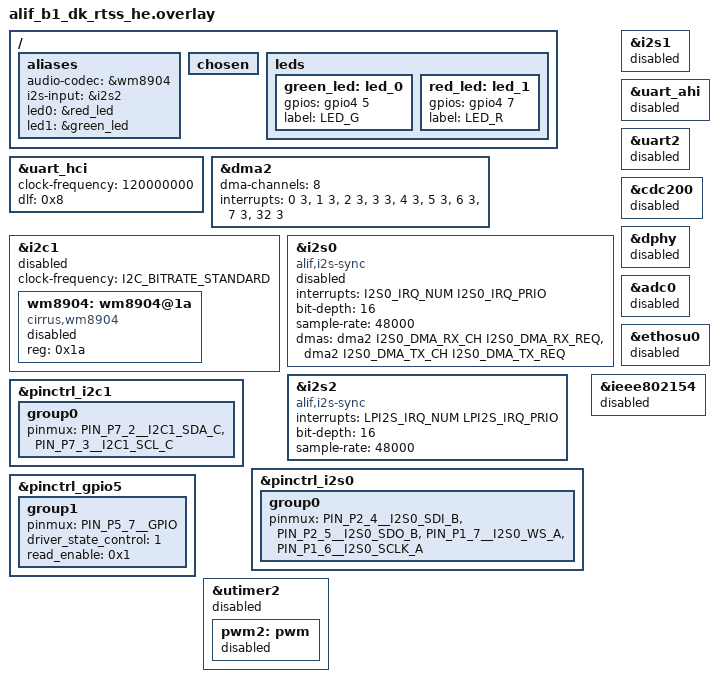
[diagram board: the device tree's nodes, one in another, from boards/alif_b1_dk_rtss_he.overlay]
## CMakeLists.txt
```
# Copyright (C) 2023 Alif Semiconductor - All Rights Reserved.
# Use, distribution and modification of this code is permitted under the
# terms stated in the Alif Semiconductor Software License Agreement
#
# You should have received a copy of the Alif Semiconductor Software
# License Agreement with this file. If not, please write to:
# contact@alifsemi.com, or visit: https://alifsemi.com/license

cmake_minimum_required(VERSION 3.20.0)
find_package(Zephyr REQUIRED HINTS $ENV{ZEPHYR_BASE})
project(le_audio_broadcast_source)

target_sources(app PRIVATE
    src/main.c
    src/broadcast_source.c
    src/audio_datapath.c
    src/mic_source.c
    src/power_config.c
)
```

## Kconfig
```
#Copyright(C) 2023 Alif Semiconductor - All Rights Reserved.
#Use, distribution and modification of this code is permitted under the
#terms stated in the Alif Semiconductor Software License Agreement
#
#You should have received a copy of the Alif Semiconductor Software
#License Agreement with this file.If not, please write to:
#contact @alifsemi.com, or visit : https: // alifsemi.com/license

menu "Alif Bluetooth LE Audio Broadcast Source"

config BLE_DEVICE_NAME
	string "BLE device name"
	default "ALIF_ZEPHYR"
	help
	  Device name to be included in advertising packets

config BROADCAST_NAME
	string "LE audio broadcast name"
	default "ALIF_LE_AUDIO"

config LE_AUDIO_PRESENTATION_DELAY_MS
	int "Presentation delay in ms"
	default 40
	help
	  LE audio presentation delay in ms. For the audio source use-case, this is defined as the
	  time in ms from the start of recording an audio frame, to the SDU reference anchor point
	  at which the SDU containing the same audio frame is sent over BLE. The absolute minimum
	  possible presentation delay would be the frame length (10 ms) plus the encoding time of
	  the frame, since it is impossible to send the frame before it has been fully recorded and
	  encoded. But some margin should be added on top of this to account for any overhead and
	  timing variations due to other activities of the software occurring while recording and
	  encoding the audio.

config APP_PRINT_STATS
	bool "Print info about send SDUs"
	depends on LOG

config APP_PRINT_STATS_INTERVAL
	int "Interval for printing info about send frames, in SDU count"
	default 1024
	depends on APP_PRINT_STATS
	help
	  Interval at which to print presentation delay statistics. The interval is measured in SDU
	  count, e.g. 1024 means to print the statistics every 512 SDUs (per channel). With a 10 ms
	  SDU interval this is around 10 seconds.

config MICROPHONE_GAIN
	int "Microphone gain in percentage"
	default 800
	range 100 1000

config INPUT_VOLUME_LEVEL
	int "Input volume level in percentage when MIC input is active"
	default 33
	range 10 100

config POWER_CONFIGURATION
	bool "Power configuration"
	default n

menu "Logging"

module = MAIN
module-str = main
source "subsys/logging/Kconfig.template.log_config"

module = BROADCAST_SOURCE
module-str = broadcast_source
source "subsys/logging/Kconfig.template.log_config"

module = AUDIO_DATAPATH
module-str = audio_datapath
source "subsys/logging/Kconfig.template.log_config"

endmenu # "Logging"

endmenu # "Alif Bluetooth LE Audio Broadcast Source"

source "Kconfig.zephyr"
```

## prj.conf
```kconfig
# Copyright (C) 2023 Alif Semiconductor - All Rights Reserved.
# Use, distribution and modification of this code is permitted under the
# terms stated in the Alif Semiconductor Software License Agreement
#
# You should have received a copy of the Alif Semiconductor Software
# License Agreement with this file. If not, please write to:
# contact@alifsemi.com, or visit: https://alifsemi.com/license
CONFIG_BT=y
CONFIG_BT_CUSTOM=y
CONFIG_ALIF_ROM_LC3_CODEC=y
CONFIG_ALIF_BLE_AUDIO=y

# CONFIG_TIMER_READS_ITS_FREQUENCY_AT_RUNTIME=y
#CONFIG_SYS_CLOCK_HW_CYCLES_PER_SEC=160000000
CONFIG_SYS_CLOCK_HW_CYCLES_PER_SEC=120000000
# not sure whether these are working or not...
#CONFIG_SYS_CLOCK_HW_CYCLES_PER_SEC=80000000
#CONFIG_SYS_CLOCK_HW_CYCLES_PER_SEC=60000000

CONFIG_USE_DYNAMIC_CLOCK_ADJUSTMENT=n
CONFIG_ALIF_BLE_SYNC_TIMER_UTIMER_ENABLED=n
CONFIG_POWER_CONFIGURATION=n

#CONFIG_LOG=y
#CONFIG_LOG_MODE_IMMEDIATE=y
#CONFIG_LOG_MODE_MINIMAL=y
CONFIG_CONSOLE=n
CONFIG_UART_CONSOLE=n
CONFIG_PRINTK=n

CONFIG_PRESENTATION_COMPENSATION_DIRECTION_SOURCE=y

CONFIG_AUDIO=y
CONFIG_AUDIO_CODEC=y
# CONFIG_AUDIO_CODEC_SHELL=y
# CONFIG_SHELL=y

# This is specific to whichever clock you use. Currently presentation layer is
# commented out so this does nothing
CONFIG_AUDIO_CLOCK_DIVIDER=1

# Should be replaced by TRNG when support is available
CONFIG_TEST_RANDOM_GENERATOR=y

# malloc support is required, simplest way is using newlib although it would also be possible to
# configure heap for picolibc
CONFIG_NEWLIB_LIBC=y

# Driver support for audio
CONFIG_I2S=y
CONFIG_I2S_SYNC_BUFFER_FORMAT_SEQUENTIAL=n
CONFIG_DMA=y

CONFIG_BROADCAST_NAME="ALIF_LE_AUDIO"

# Audio driver support specific to B1 DK board.
# Audio codec is WM8904, connected via I2C.
CONFIG_I2C=y
CONFIG_WM8904=y

CONFIG_I2C_INIT_PRIORITY=50
CONFIG_WM8904_INIT_PRIORITY=99

# For MRAM(XIP) builds with LLVM exception tables cause linker errors as part of the code is placed to TCM
CONFIG_EXCEPTIONS=n
```

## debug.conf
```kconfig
CONFIG_LOG=y
CONFIG_LOG_MODE_IMMEDIATE=y
CONFIG_LOG_MODE_MINIMAL=y
CONFIG_CONSOLE=y
CONFIG_UART_CONSOLE=y
```

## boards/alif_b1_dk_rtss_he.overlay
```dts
/* Copyright (C) 2023 Alif Semiconductor - All Rights Reserved.
 * Use, distribution and modification of this code is permitted under the
 * terms stated in the Alif Semiconductor Software License Agreement
 *
 * You should have received a copy of the Alif Semiconductor Software
 * License Agreement with this file. If not, please write to:
 * contact@alifsemi.com, or visit: https: //alifsemi.com/license
 *
 */

#include <dt-bindings/pinctrl/balletto-pinctrl.h>
#include <dt-bindings/i2c/i2c.h>
#include <dt-bindings/gpio/gpio.h>

#define I2S0_IRQ_NUM  141
#define I2S0_IRQ_PRIO 3

#define LPI2S_IRQ_NUM  48
#define LPI2S_IRQ_PRIO 3

#define I2S0_DMA_RX_CH  2
#define I2S0_DMA_RX_REQ 24
#define I2S0_DMA_TX_CH  3
#define I2S0_DMA_TX_REQ 28

#define LPI2S_DMA_RX_CH  4
#define LPI2S_DMA_RX_REQ 14
#define LPI2S_DMA_TX_CH  5
#define LPI2S_DMA_TX_REQ 15

#define AUDIO_DMA_ENABLED 1
/* TODO: check MIC DMA for some weird error when used multiple times */
#define MIC_DMA_ENABLED 0

#define HW_CORE_CLOCK 120

/ {
	aliases {
		audio-codec = &wm8904;
		i2s-input = &i2s2;
		/*i2s-mic = &i2s2;*/

		led0 = &red_led;
		led1 = &green_led;
	};

	chosen {
		/delete-property/ zephyr,console;
		/delete-property/ zephyr,shell-uart;
		/delete-property/ zephyr,uart-mcumgr;
	};

	leds {
		green_led: led_0 {
			gpios = < &gpio4 5 GPIO_ACTIVE_HIGH >;
			label = "LED_G";
		};
		red_led: led_1 {
			gpios = < &gpio4 7 GPIO_ACTIVE_HIGH >;
			label = "LED_R";
		};
	};
};

&uart_hci {
#if HW_CORE_CLOCK == 120
	clock-frequency = < 120000000 >;
	dlf = < 0x8 >;
#elif HW_CORE_CLOCK == 80
	clock-frequency = < 80000000 >;
	dlf = < 0xB >;
#elif HW_CORE_CLOCK == 60
	clock-frequency = < 60000000 >;
	dlf = < 0x4 >;
#else
	clock-frequency = < 160000000 >;
	dlf = < 0x5 >;
#endif
};

&dma2 {
	status = "okay";
	dma-channels = <8>;
	interrupts = <0 3>, <1 3>, <2 3>, <3 3>, <4 3>, <5 3>,
		     <6 3>, <7 3>, <32 3>;
	interrupt-names = "channel0", "channel1",
			  "channel2", "channel3",
			  "channel4", "channel5",
			  "channel6", "channel7",
			  "abort";
};

&i2c1 {
	clock-frequency = <I2C_BITRATE_STANDARD>;
	status = "disabled";

	wm8904: wm8904@1a {
		compatible = "cirrus,wm8904";
		reg = <0x1a>;
		status = "disabled";
	};
};

&i2s0 {
	/delete-property/ clock-frequency;
	/delete-property/ driver_instance;
	compatible = "alif,i2s-sync";
	interrupts = <I2S0_IRQ_NUM I2S0_IRQ_PRIO>;
	bit-depth = <16>;
	sample-rate = <48000>;
	status = "disabled";
#if AUDIO_DMA_ENABLED
	dmas = <&dma2 I2S0_DMA_RX_CH I2S0_DMA_RX_REQ>,
	       <&dma2 I2S0_DMA_TX_CH I2S0_DMA_TX_REQ>;
	dma-names = "rxdma", "txdma";
#endif
};

&i2s2 {
	/delete-property/ clock-frequency;
	/delete-property/ driver_instance;
	compatible = "alif,i2s-sync";
	interrupts = <LPI2S_IRQ_NUM LPI2S_IRQ_PRIO>;
	bit-depth = <16>;
	sample-rate = <48000>;
	status = "okay";
#if MIC_DMA_ENABLED
	dmas = <&dma2 LPI2S_DMA_RX_CH LPI2S_DMA_RX_REQ>,
	       <&dma2 LPI2S_DMA_TX_CH LPI2S_DMA_TX_REQ>;
	dma-names = "rxdma", "txdma";
#endif
};

&pinctrl_i2c1 {
	group0 {
		pinmux = <PIN_P7_2__I2C1_SDA_C>,
			 <PIN_P7_3__I2C1_SCL_C>;
	};
};

&pinctrl_i2s0 {
	group0 {
		pinmux = <PIN_P2_4__I2S0_SDI_B>,
			 <PIN_P2_5__I2S0_SDO_B>,
			 <PIN_P1_7__I2S0_WS_A>,
			 <PIN_P1_6__I2S0_SCLK_A>;
	};
};

/* Jouystick middle button */
&pinctrl_gpio5 {
	group1 {
		pinmux = <PIN_P5_7__GPIO>;
		driver_state_control = <1>;
		read_enable = < 0x1 >;
	};
};

/* Disable unnecessary nodes */
&i2s1 {
	status = "disabled";
};
&uart_ahi {
	status = "disabled";
};


&uart2 {
	status = "disabled";
};


&utimer2 {
	status = "disabled";
	pwm2: pwm {
		status = "disabled";
	};
};
&cdc200 {
	status = "disabled";
};
&dphy {
	status = "disabled";
};
&adc0 {
	status = "disabled";
};
&ethosu0 {
	status = "disabled";
};
&ieee802154 {
	status = "disabled";
};


/*
&crc {
	status = "disabled";
};
&rng {
	status = "disabled";
};
*/
```

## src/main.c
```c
/* Copyright (C) 2023 Alif Semiconductor - All Rights Reserved.
 * Use, distribution and modification of this code is permitted under the
 * terms stated in the Alif Semiconductor Software License Agreement
 *
 * You should have received a copy of the Alif Semiconductor Software
 * License Agreement with this file. If not, please write to:
 * contact@alifsemi.com, or visit: https://alifsemi.com/license
 */

#include <zephyr/kernel.h>
#include <zephyr/drivers/gpio.h>
#include <zephyr/logging/log.h>
#include <zephyr/sys/__assert.h>
#include "alif_ble.h"
#include "gapm.h"
#include "gap_le.h"
#include "broadcast_source.h"
#include "audio_datapath.h"
#include "power_config.h"

LOG_MODULE_REGISTER(main, CONFIG_MAIN_LOG_LEVEL);

#define MIC_ENABLED (DT_NODE_EXISTS(DT_ALIAS(i2s_mic)) && DT_NODE_EXISTS(DT_ALIAS(sw0)))

static const struct gpio_dt_spec led_on = GPIO_DT_SPEC_GET_OR(DT_ALIAS(led1), gpios, {0});

#if MIC_ENABLED
static const struct gpio_dt_spec button = GPIO_DT_SPEC_GET_OR(DT_ALIAS(sw0), gpios, {0});
static const struct gpio_dt_spec led_mic = GPIO_DT_SPEC_GET_OR(DT_ALIAS(led0), gpios, {0});

#if CONFIG_I2S_SYNC_BUFFER_FORMAT_SEQUENTIAL
#error "Sequential buffer format is not supported"
#endif
#endif

/**
 * Bluetooth stack configuration
 */
static const gapm_config_t gapm_cfg = {
	.role = GAP_ROLE_LE_BROADCASTER,
	.pairing_mode = GAPM_PAIRING_DISABLE,
	.privacy_cfg = 0,
	.renew_dur = 1500,
	.private_identity.addr = {0, 0, 0, 0, 0, 0},
	.irk.key = {0, 0, 0, 0, 0, 0, 0, 0, 0, 0, 0, 0, 0, 0, 0, 0},
	.gap_start_hdl = 0,
	.gatt_start_hdl = 0,
	.att_cfg = 0,
	.sugg_max_tx_octets = GAP_LE_MAX_OCTETS,
	/* Use the minimum transmission time to minimize latency */
	.sugg_max_tx_time = GAP_LE_MIN_TIME,
	.tx_pref_phy = GAP_PHY_ANY,
	.rx_pref_phy = GAP_PHY_ANY,
	.tx_path_comp = 0,
	.rx_path_comp = 0,
	.class_of_device = 0,  /* BT Classic only */
	.dflt_link_policy = 0, /* BT Classic only */
};

#if !CONFIG_ALIF_BLE_ROM_IMAGE_V1_0 /* ROM version > 1.0 */
static void on_gapm_err(uint32_t metainfo, uint8_t code)
{
	LOG_ERR("gapm error %d", code);
}

static const gapm_cb_t gapm_err_cbs = {
	.cb_hw_error = on_gapm_err,
};

/* For the broadcaster role, callbacks are not mandatory */
static const gapm_callbacks_t gapm_cbs = {
	.p_con_req_cbs = NULL,
	.p_sec_cbs = NULL,
	.p_info_cbs = NULL,
	.p_le_config_cbs = NULL,
	.p_bt_config_cbs = NULL,
	.p_gapm_cbs = &gapm_err_cbs,
};
#else /* ROM version 1.0 */
static void on_gapm_err(enum co_error err)
{
	LOG_ERR("gapm error %d", err);
}

static const gapm_err_info_config_cb_t gapm_err_cbs = {
	.ctrl_hw_error = on_gapm_err,
};

/* For the broadcaster role, callbacks are not mandatory */
static const gapm_callbacks_t gapm_cbs = {
	.p_con_req_cbs = NULL,
	.p_sec_cbs = NULL,
	.p_info_cbs = NULL,
	.p_le_config_cbs = NULL,
	.p_bt_config_cbs = NULL,
	.p_err_info_config_cbs = &gapm_err_cbs,
};
#endif

static void on_gapm_process_complete(uint32_t metainfo, uint16_t status)
{
	if (status) {
		LOG_ERR("gapm process completed with error %u", status);
		return;
	}

	LOG_DBG("gapm process completed successfully");

	int ret = broadcast_source_start();

	if (ret != 0) {
		LOG_ERR("Failed to start broadcast source with error %d", ret);
	}
	gpio_pin_set_dt(&led_on, ret == 0);
}

#if MIC_ENABLED

#define BUTTON_DEBOUNCE_MS  5
#define PTT_MINIMUM_TIME_MS 200
#define BUTTON_INVERTED     true

static void set_led(bool const state)
{
	if (!led_mic.port) {
		return;
	}
	gpio_pin_set_dt(&led_mic, state);
}

static bool get_button_state(void)
{
	if (!button.port) {
		return false;
	}
	return !!gpio_pin_get_dt(&button) ^ BUTTON_INVERTED;
}

static void stop_push_to_talk(struct k_work *work)
{
	ARG_UNUSED(work);
	/* Stop push to talk.... */
	audio_datapath_mic_control(false);
	set_led(false);
}

static K_WORK_DELAYABLE_DEFINE(stop_ptt_work, stop_push_to_talk);

static bool last_button_state = true;

static void debounce_expired(struct k_work *work)
{
	ARG_UNUSED(work);

	bool const button_state = get_button_state();

	if (button_state == last_button_state) {
		/* Ignore if state is not changed */
		return;
	}
	last_button_state = button_state;

	if (button_state) {
		/* pressed... */
#if button_set_power
		power_config_set_wrapper();
#else
		(void)k_work_cancel_delayable(&stop_ptt_work);
		audio_datapath_mic_control(true);
		set_led(true);
#endif
		return;
	}

#if !button_set_power
	/* Delay shutdown a bit to avoid weird behaviors */
	k_work_reschedule(&stop_ptt_work, K_MSEC(PTT_MINIMUM_TIME_MS));
#endif
}

static K_WORK_DELAYABLE_DEFINE(debounce_work, debounce_expired);

static void button_pressed(const struct device *dev, struct gpio_callback *cb, uint32_t pins)
{
	k_work_reschedule(&debounce_work, K_MSEC(BUTTON_DEBOUNCE_MS));
}

static int configure_button(void)
{
	static struct gpio_callback button_cb_data;

	/* Configure button */
	if (!gpio_is_ready_dt(&button)) {
		LOG_WRN("Button is not ready or not configured... ignore");
		return 0;
	}

	if (gpio_pin_configure_dt(&button, GPIO_INPUT)) {
		LOG_ERR("Button configure failed");
		return -1;
	}

	if (gpio_pin_interrupt_configure_dt(&button, GPIO_INT_EDGE_BOTH) != 0) {
		LOG_ERR("button int conf failed");
		return -1;
	}

	gpio_init_callback(&button_cb_data, button_pressed, BIT(button.pin));
	if (gpio_add_callback(button.port, &button_cb_data) != 0) {
		LOG_ERR("cb add failed");
		return -1;
	}

	last_button_state = get_button_state();

	LOG_INF("push-to-talk functionality enabled");

	return 0;
}

static int configure_led(void)
{
	if (!gpio_is_ready_dt(&led_mic)) {
		return 0;
	}

	if (gpio_pin_configure_dt(&led_mic, GPIO_OUTPUT_ACTIVE)) {
		LOG_ERR("led_mic configure failed");
		return -1;
	}

	set_led(false);
	return 0;
}
#else
#define configure_button() 0
#define configure_led()    0
#endif

int main(void)
{
	power_config_set_default_wrapper();
	//power_config_get_and_print_wrapper();

	if (!gpio_is_ready_dt(&led_on)) {
		return 0;
	}

	if (gpio_pin_configure_dt(&led_on, GPIO_OUTPUT_ACTIVE)) {
		LOG_ERR("led_on configure failed");
		return -1;
	}

	gpio_pin_set_dt(&led_on, false);

	if (configure_button()) {
		return -1;
	}

	if (configure_led()) {
		return -1;
	}

	int ret = alif_ble_enable(NULL);

	if (ret) {
		LOG_ERR("Failed to enable bluetooth, err %d", ret);
		return ret;
	}

	LOG_DBG("BLE enabled");

#if !button_set_power
	/* Power config can be done after BLE wakeup (SE is not needed anymore) */
	if (power_config_set_wrapper()) {
		return -1;
	}
#endif

	uint16_t err = gapm_configure(0, &gapm_cfg, &gapm_cbs, on_gapm_process_complete);

	if (err != 0) {
		LOG_ERR("gapm_configure error %u", err);
		return -1;
	}

	while (1) {
		k_sleep(K_SECONDS(5));
	}

	return 0;
}
```

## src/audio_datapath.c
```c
/* Copyright (C) 2025 Alif Semiconductor - All Rights Reserved.
 * Use, distribution and modification of this code is permitted under the
 * terms stated in the Alif Semiconductor Software License Agreement
 *
 * You should have received a copy of the Alif Semiconductor Software
 * License Agreement with this file. If not, please write to:
 * contact@alifsemi.com, or visit: https://alifsemi.com/license
 */

#include <zephyr/kernel.h>
#include <zephyr/device.h>
#include <zephyr/logging/log.h>
#include <zephyr/audio/codec.h>
#include "bluetooth/le_audio/audio_encoder.h"
#include "bluetooth/le_audio/audio_source_i2s.h"
#include "audio_datapath.h"
#include "mic_source.h"

LOG_MODULE_REGISTER(audio_datapath, CONFIG_AUDIO_DATAPATH_LOG_LEVEL);

#define MIC_LEVEL_CALC(_s)   (((int)(_s) * CONFIG_MICROPHONE_GAIN) / 100)
#define INPUT_LEVEL_CALC(_s) (((int)(_s) * CONFIG_INPUT_VOLUME_LEVEL) / 100)

#define I2S_NODE     DT_ALIAS(i2s_input)
#define I2S_MIC_NODE DT_ALIAS(i2s_mic)
#define CODEC_NODE   DT_ALIAS(audio_codec)

const struct device *i2s_dev = DEVICE_DT_GET(I2S_NODE);
const struct device *codec_dev = DEVICE_DT_GET_OR_NULL(CODEC_NODE);
const struct device *i2s_mic_dev = DEVICE_DT_GET_OR_NULL(I2S_MIC_NODE);

/* Audio datapath handles */
static struct audio_encoder *audio_encoder;

#if CONFIG_APP_PRINT_STATS
static void on_frame_complete(void *param, uint32_t timestamp, uint16_t sdu_seq)
{
	if ((sdu_seq % CONFIG_APP_PRINT_STATS_INTERVAL) == 0) {
		LOG_INF("SDU sequence number: %u", sdu_seq);
	}
}
#endif

#ifdef CONFIG_PRESENTATION_COMPENSATION_DEBUG
void on_timing_debug_info_ready(struct presentation_comp_debug_data *dbg_data)
{
	LOG_INF("Presentation compensation debug data is ready");
}
#endif

static int configure_codec(const uint32_t sampling_rate_hz)
{
	if (!codec_dev) {
		LOG_DBG("Codec device is not ready");
		return 0;
	}

	int ret;
	/* clang-format off */
	struct audio_codec_cfg codec_cfg = {
		.dai_type = AUDIO_DAI_TYPE_I2S,
		.dai_cfg = {
			.i2s = {
				.word_size = AUDIO_PCM_WIDTH_16_BITS,
				.channels = 2,
				.format = I2S_FMT_DATA_FORMAT_I2S,
				.options = 0,
				.frame_clk_freq = sampling_rate_hz,
				.mem_slab = NULL,
				.block_size = 0,
				.timeout = 0,
			},
		},
	};
	/* clang-format on */

	/* Configure codec */
	ret = audio_codec_configure(codec_dev, &codec_cfg);
	if (ret) {
		LOG_ERR("Failed to configure source codec. err %d", ret);
		return ret;
	}
	audio_codec_start_output(codec_dev);

	return 0;
}

__ramfunc static void audio_encoder_mixer_thread_func(void *p1, void *p2, void *p3)
{
	/* thread:
	 * get audio input jack buffer
	 * if audio_queue_mic has data available
	 *     adjust mic gain
	 *     lower input audio gain
	 *     mix mic and audio input samples
	 *     free mic data
	 * end
	 * push audio samples to LC3 encoder
	 * free audio input buffer
	 */

	struct audio_queue *audio_queue_in1 = p1; /* input I2S codec (WM8904) */
	struct audio_queue *audio_queue_in2 = p2; /* input I2S MIC */
	struct audio_queue *audio_queue_out = p3; /* output (to LC3 encoder) */
	struct audio_block *audio_in1;
	struct audio_block *audio_in2;
	struct audio_block *audio_out;
	int ret;

	LOG_DBG("Mixer thread started");

	while (1) {
		audio_out = audio_in2 = audio_in1 = NULL;
		ret = k_msgq_get(&audio_queue_in1->msgq, &audio_in1, K_FOREVER);
		if (ret || !audio_in1) {
			continue;
		}

		ret = k_msgq_get(&audio_queue_in2->msgq, &audio_in2, K_NO_WAIT);
		if (!ret && audio_in2) {
			/* Do mixing... */
			size_t const samples =
				audio_queue_in2->audio_block_samples * audio_in2->num_channels;
			pcm_sample_t *p_mic_data = audio_in2->channels[0];
			bool const mic_has_right_channel = audio_in2->num_channels > 1;

			pcm_sample_t *p_input_left = audio_in1->channels[0];
			pcm_sample_t *p_input_right =
				audio_in1->num_channels > 1 ? audio_in1->channels[1] : NULL;
			pcm_sample_t data;

			for (size_t sample = 0; sample < samples; sample++) {
				data = *p_mic_data++;
				data = MIC_LEVEL_CALC(data);

				if ((sample & 1) && mic_has_right_channel) { /* Right channel */
					if (p_input_right) {
						*p_input_right =
							data + INPUT_LEVEL_CALC(*p_input_right);
						p_input_right++;
					}
				} else { /* Left channel */
					*p_input_left = data + INPUT_LEVEL_CALC(*p_input_left);
					p_input_left++;
				}
			}
			k_mem_slab_free(&audio_queue_in2->slab, audio_in2);
		}

		ret = k_mem_slab_alloc(&audio_queue_out->slab, (void **)&audio_out, K_NO_WAIT);
		if (ret || !audio_out) {
			k_mem_slab_free(&audio_queue_in1->slab, audio_in1);
			continue;
		}

		/* Copy in1 to out */
		memcpy(audio_out, audio_in1, sizeof(*audio_out));

		ret = k_msgq_put(&audio_queue_out->msgq, &audio_out, K_NO_WAIT);
		if (ret) {
			k_mem_slab_free(&audio_queue_out->slab, audio_out);
		}
		k_mem_slab_free(&audio_queue_in1->slab, audio_in1);
	}
}

static int configure_mic_input(void)
{
	/*
	 * Two I2S input queues are used:
	 *   - audio jack I2S input (audio_queue_i2s)
	 *   - mic I2S input (audio_queue_mic)
	 *
	 * Configured (audio encoder input) audio I2S input queue will be changed
	 * to audio_queue_i2s and the created thread will mix audio_queue_mic
	 * into audio_queue_i2s. Result will be copied and pushed to
	 * audio_queue_current (audio encoder input queue).
	 */

	struct audio_queue *audio_queue_current = audio_encoder_audio_queue_get(audio_encoder);

	if (!audio_queue_current) {
		LOG_ERR("Failed to get audio queue");
		return -ENODEV;
	}

	struct audio_queue *audio_queue_mic, *audio_queue_i2s;

	audio_queue_mic = audio_queue_create(audio_queue_current->item_count,
					     audio_queue_current->sampling_freq_hz,
					     audio_queue_current->frame_duration_us);

	if (!audio_queue_mic) {
		LOG_ERR("Failed to create audio queue");
		return -ENOMEM;
	}

	audio_queue_i2s = audio_queue_create(audio_queue_current->item_count,
					     audio_queue_current->sampling_freq_hz,
					     audio_queue_current->frame_duration_us);

	if (!audio_queue_i2s) {
		audio_queue_delete(audio_queue_mic);
		LOG_ERR("Failed to create audio queue");
		return -ENOMEM;
	}

	int ret = audio_source_i2s_configure(i2s_dev, audio_queue_i2s);

	if (ret != 0) {
		audio_queue_delete(audio_queue_i2s);
		audio_queue_delete(audio_queue_mic);
		LOG_ERR("Failed to configure audio source I2S, err %d", ret);
		return ret;
	}

	ret = mic_i2s_configure(i2s_mic_dev, audio_queue_mic);
	if (ret != 0) {
		audio_queue_delete(audio_queue_i2s);
		audio_queue_delete(audio_queue_mic);
		LOG_ERR("Failed to configure mic I2S, err %d", ret);
		return ret;
	}

	static struct k_thread mixer_thread;

	static K_THREAD_STACK_DEFINE(mixer_thread_stack, 2048);

	k_tid_t tid = k_thread_create(
		&mixer_thread, mixer_thread_stack, K_THREAD_STACK_SIZEOF(mixer_thread_stack),
		audio_encoder_mixer_thread_func, audio_queue_i2s, audio_queue_mic,
		audio_queue_current, CONFIG_ALIF_BLE_HOST_THREAD_PRIORITY + 1, 0, K_NO_WAIT);

	if (!tid) {
		audio_queue_delete(audio_queue_i2s);
		audio_queue_delete(audio_queue_mic);
		LOG_ERR("Failed to create mixer thread");
		return -EINVAL;
	}

	k_thread_name_set(tid, "mixer");

	return 0;
}

int audio_datapath_init(void)
{
	if (!device_is_ready(i2s_dev)) {
		LOG_ERR("I2S device is not ready");
		return -ENODEV;
	}
	if (codec_dev && !device_is_ready(codec_dev)) {
		LOG_ERR("Audio codec device is not ready");
		return -ENODEV;
	}
	if (i2s_mic_dev && !device_is_ready(i2s_mic_dev)) {
		LOG_ERR("I2S MIC device is not ready");
		return -1;
	}

	struct audio_encoder_params const enc_params = {
		.i2s_dev = i2s_dev,
		.frame_duration_us =
			IS_ENABLED(CONFIG_ALIF_BLE_AUDIO_FRAME_DURATION_10MS) ? 10000 : 7500,
		.sampling_rate_hz = CONFIG_ALIF_BLE_AUDIO_FS_HZ,
		.audio_buffer_len_us = 2 * CONFIG_ALIF_BLE_AUDIO_MAX_TLATENCY,
	};

	audio_encoder_delete(audio_encoder);

	configure_codec(enc_params.sampling_rate_hz);

	audio_encoder = audio_encoder_create(&enc_params);
	if (!audio_encoder) {
		LOG_ERR("Failed to create audio encoder");
		return -ENODEV;
	}

#if CONFIG_APP_PRINT_STATS
	int ret = audio_encoder_register_cb(audio_encoder, on_frame_complete, NULL);

	if (ret != 0) {
		LOG_ERR("Failed to register encoder cb for stats, err %d", ret);
		return ret;
	}
#endif

	if (i2s_mic_dev && configure_mic_input() != 0) {
		LOG_ERR("Failed to configure mic input");
		return -1;
	}

	return 0;
}

int audio_datapath_channel_create(const size_t octets_per_frame, const uint8_t stream_lid)
{
	int ret = audio_encoder_add_channel(audio_encoder, octets_per_frame, stream_lid);

	if (ret) {
		LOG_ERR("Channel %u creation failed. Err %d", stream_lid, ret);
		return ret;
	}
	return 0;
}

void audio_datapath_start(const uint8_t stream_lid)
{
	int retval;

	retval = audio_encoder_start_channel(audio_encoder, stream_lid);
	if (retval != 0) {
		LOG_ERR("Failed to start channel %d, err %d", stream_lid, retval);
		__ASSERT(false, "Failed to start channel");
	}
}

void audio_datapath_mic_control(bool const start)
{
	/* Do nothing if audio encoder is not initialized */
	if (!audio_encoder) {
		return;
	}

	if (start) {
		LOG_INF("MIC start...");
		mic_i2s_start();
		return;
	}

	LOG_INF("MIC stop...");
	mic_i2s_stop();
}
```

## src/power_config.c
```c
#include <zephyr/logging/log.h>
#include <soc.h>

#include "power_config.h"
#include "se_service.h"

LOG_MODULE_REGISTER(power_config, CONFIG_MAIN_LOG_LEVEL);

#define DCDC_VOLTAGE_REG1 0x1a60a030
#define DCDC_VOLTAGE_REG2 0x1a60a034

union dcdc_voltage_reg1 {
	uint32_t raw;
	struct {
		uint32_t standby_mode_bypass: 1;
		uint32_t standby_mode_bypass_val: 1;
		uint32_t force_LS_on: 1;
		uint32_t dcdc_trim_vout: 6;
		uint32_t dcdc_osc2M_ibias: 4;
		uint32_t reserved: 4;
		uint32_t dcdc_en_xtal_clk: 1;
		uint32_t en_drv_dly_cont: 4;
		uint32_t en_ss_dly_cont: 4;
		uint32_t ss_done_dly_cont: 4;
		uint32_t soc_ena_0p8_bypass: 1;
		uint32_t soc_ena_0p8_bypass_val: 1;
	};
};

union dcdc_voltage_reg2 {
	uint32_t raw;
	struct {
		uint32_t trim_ss: 3;
		uint32_t trim_ZCD: 3;
		uint32_t tst_oneshot: 1;
		uint32_t oneshot_I_cont: 4;
		uint32_t phy_ldo_cont: 4;
		uint32_t trim_oneshot_cap: 4;
		uint32_t reserved: 6;
		uint32_t dcdc_xtal_div_cont: 6;
		uint32_t dcdc_xtal_div_en: 1;
	};
};

static int dcdc_reg_print(void)
{
	union dcdc_voltage_reg1 const reg1 = {
		.raw = sys_read32(DCDC_VOLTAGE_REG1),
	};
	union dcdc_voltage_reg2 const reg2 = {
		.raw = sys_read32(DCDC_VOLTAGE_REG2),
	};

	LOG_INF("DCDC REG1: %d", reg1.raw);
	LOG_INF("  soc_ena_0p8_bypass_val: %d", reg1.soc_ena_0p8_bypass_val);
	LOG_INF("  soc_ena_0p8_bypass: %d", reg1.soc_ena_0p8_bypass);
	LOG_INF("  ss_done_dly_cont: %d", reg1.ss_done_dly_cont);
	LOG_INF("  en_ss_dly_cont: %d", reg1.en_ss_dly_cont);
	LOG_INF("  en_drv_dly_cont: %d", reg1.en_drv_dly_cont);
	LOG_INF("  dcdc_en_xtal_clk: %d", reg1.dcdc_en_xtal_clk);
	LOG_INF("  reserved: %d", reg1.reserved);
	LOG_INF("  dcdc_osc2M_ibias: %d", reg1.dcdc_osc2M_ibias);
	LOG_INF("  dcdc_trim_vout: %d", reg1.dcdc_trim_vout);
	LOG_INF("  force_LS_on: %d", reg1.force_LS_on);
	LOG_INF("  standby_mode_bypass_val: %d", reg1.standby_mode_bypass_val);
	LOG_INF("  standby_mode_bypass: %d", reg1.standby_mode_bypass);

	LOG_INF("DCDC REG2: %d", reg2.raw);
	LOG_INF("  dcdc_xtal_div_en: %d", reg2.dcdc_xtal_div_en);
	LOG_INF("  dcdc_xtal_div_cont: %d", reg2.dcdc_xtal_div_cont);
	LOG_INF("  reserved: %d", reg2.reserved);
	LOG_INF("  trim_oneshot_cap: %d", reg2.trim_oneshot_cap);
	LOG_INF("  phy_ldo_cont: %d", reg2.phy_ldo_cont);
	LOG_INF("  oneshot_I_cont: %d", reg2.oneshot_I_cont);
	LOG_INF("  tst_oneshot: %d", reg2.tst_oneshot);
	LOG_INF("  trim_ZCD: %d", reg2.trim_ZCD);
	LOG_INF("  trim_ss: %d", reg2.trim_ss);

	return 0;
}

static int power_config_print(run_profile_t const *const profile)
{
	LOG_INF("-------------------------------");
	LOG_INF("power domains: 0x%x", profile->power_domains);
	if (profile->power_domains & PD_VBAT_AON_MASK) {
		LOG_INF("  PD_VBAT_AON");
	}
	if (profile->power_domains & PD_SRAM_CTRL_AON_MASK) {
		LOG_INF("  PD_SRAM_CTRL_AON");
	}
	if (profile->power_domains & PD_SSE700_AON_MASK) {
		LOG_INF("  PD_SSE700_AON");
	}
	if (profile->power_domains & PD_RTSS_HE_MASK) {
		LOG_INF("  PD_RTSS_HE");
	}
	if (profile->power_domains & PD_SRAMS_MASK) {
		LOG_INF("  PD_SRAMS");
	}
	if (profile->power_domains & PD_SESS_MASK) {
		LOG_INF("  PD_SESS");
	}
	if (profile->power_domains & PD_SYST_MASK) {
		LOG_INF("  PD_SYST");
	}
	if (profile->power_domains & PD_RTSS_HP_MASK) {
		LOG_INF("  PD_RTSS_HP");
	}
	if (profile->power_domains & PD_DBSS_MASK) {
		LOG_INF("  PD_DBSS");
	}
	if (profile->power_domains & PD2_APPS_MASK) {
		LOG_INF("  PD2_APPS");
	}

	LOG_INF("memory blocks: 0x%x", profile->memory_blocks);
	if (profile->memory_blocks & SRAM2_MASK) {
		LOG_INF("  SRAM2");
	}
	if (profile->memory_blocks & SRAM3_MASK) {
		LOG_INF("  SRAM3");
	}
	if (profile->memory_blocks & SRAM4_1_MASK) {
		LOG_INF("  SRAM4_1");
	}
	if (profile->memory_blocks & SRAM4_2_MASK) {
		LOG_INF("  SRAM4_2");
	}
	if (profile->memory_blocks & SRAM4_3_MASK) {
		LOG_INF("  SRAM4_3");
	}
	if (profile->memory_blocks & SRAM4_4_MASK) {
		LOG_INF("  SRAM4_4");
	}
	if (profile->memory_blocks & SRAM5_1_MASK) {
		LOG_INF("  SRAM5_1");
	}
	if (profile->memory_blocks & SRAM5_2_MASK) {
		LOG_INF("  SRAM5_2");
	}
	if (profile->memory_blocks & SRAM5_3_MASK) {
		LOG_INF("  SRAM5_3");
	}
	if (profile->memory_blocks & SRAM5_4_MASK) {
		LOG_INF("  SRAM5_4");
	}
	if (profile->memory_blocks & SRAM5_5_MASK) {
		LOG_INF("  SRAM5_5");
	}
	if (profile->memory_blocks & MRAM_MASK) {
		LOG_INF("  MRAM");
	}
	if (profile->memory_blocks & OSPI0_MASK) {
		LOG_INF("  OSPI0");
	}
	if (profile->memory_blocks & OSPI1_MASK) {
		LOG_INF("  OSPI1");
	}
	if (profile->memory_blocks & SERAM_1_MASK) {
		LOG_INF("  SERAM_1");
	}
	if (profile->memory_blocks & SERAM_2_MASK) {
		LOG_INF("  SERAM_2");
	}
	if (profile->memory_blocks & SERAM_3_MASK) {
		LOG_INF("  SERAM_3");
	}
	if (profile->memory_blocks & SERAM_4_MASK) {
		LOG_INF("  SERAM_4");
	}
	if (profile->memory_blocks & FWRAM_MASK) {
		LOG_INF("  FWRAM");
	}
	if (profile->memory_blocks & BACKUP4K_MASK) {
		LOG_INF("  BACKUP4K");
	}

	LOG_INF("ip clock gating: 0x%x", profile->ip_clock_gating);
	LOG_INF("phy power gating: 0x%x", profile->phy_pwr_gating);
	LOG_INF("vdd io flex: %s", profile->vdd_ioflex_3V3 == IOFLEX_LEVEL_1V8 ? "1V8" : "3V3");
	LOG_INF("dcdc_voltage %d", profile->dcdc_voltage);

	switch (profile->dcdc_mode) {
	case DCDC_MODE_OFF:
		LOG_INF("DCDC mode: OFF");
		break;
	case DCDC_MODE_PFM_AUTO:
		LOG_INF("DCDC mode: PFM_AUTO");
		break;
	case DCDC_MODE_PFM_FORCED:
		LOG_INF("DCDC mode: PFM_FORCED");
		break;
	case DCDC_MODE_PWM:
		LOG_INF("DCDC mode: PWM");
		break;
	default:
		LOG_INF("DCDC mode: unknown");
		break;
	}

	switch (profile->aon_clk_src) {
	case CLK_SRC_LFRC:
		LOG_INF("AON clock source: LFRC");
		break;
	case CLK_SRC_LFXO:
		LOG_INF("AON clock source: LFXO");
		break;
	default:
		LOG_INF("AON clock source: unknown");
		break;
	}

	switch (profile->run_clk_src) {
	case CLK_SRC_HFRC:
		LOG_INF("Run clock source: HFRC");
		break;
	case CLK_SRC_HFXO:
		LOG_INF("Run clock source: HFXO");
		break;
	case CLK_SRC_PLL:
		LOG_INF("Run clock source: PLL");
		break;
	default:
		LOG_INF("Run clock source: unknown");
		break;
	}

	static const char *cpu_clk_freq_str[] = {
		"800", "400", "300", "200",     "160",     "120",     "80",      "60",       "100",
		"50",  "20",  "10",  "RC 76.8", "RC 38.4", "XO 76.8", "XO 38.4", "DISABLED",
	};

	if (profile->cpu_clk_freq < ARRAY_SIZE(cpu_clk_freq_str)) {
		LOG_INF("CPU clock frequency: %s MHz", cpu_clk_freq_str[profile->cpu_clk_freq]);
	} else {
		LOG_INF("CPU clock frequency: unknown");
	}

	static const char *scaled_clk_freq_str[] = {
		"RC ACTV 76.8",  "RC ACTV 38.4",   "RC ACTV 19.2", "RC ACTV 9.6",   "RC ACTV 4.8",
		"RC ACTV 2.4",   "RC ACTV 1.2",    "RC ACTV 0.6",  "RC STDBY 76.8", "RC STDBY 38.4",
		"RC STDBY 19.2", "RC STDBY 9.6",   "RC STDBY 4.8", "RC STDBY 2.4",  "RC STDBY 1.2",
		"RC STDBY 0.6",  "XO LOW 38.4",    "XO LOW 19.2",  "XO LOW 9.6",    "XO LOW 4.8",
		"XO LOW 2.4",    "XO LOW 1.2",     "XO LOW 0.6",   "XO LOW 0.3",    "XO HIGH 38.4",
		"XO HIGH 19.2",  "XO HIGH 9.6",    "XO HIGH 2.4",  "XO HIGH 0.6",   "XO HIGH 0.3",
		"XO HIGH 0.15",  "XO HIGH 0.0375",
	};

	if (profile->scaled_clk_freq < ARRAY_SIZE(scaled_clk_freq_str)) {
		LOG_INF("Scaled clock frequency: %s",
			scaled_clk_freq_str[profile->scaled_clk_freq]);
	} else {
		LOG_INF("Scaled clock frequency: unknown");
	}
	LOG_INF("-------------------------------");

	return 0;
}

int power_config_get_and_print(void)
{
	int err;
	run_profile_t profile = {0};

	err = se_service_sync();
	if (err) {
		LOG_ERR("SE: not responding to service calls %d", err);
		return err;
	}

	err = se_service_get_run_cfg(&profile);
	if (err) {
		LOG_ERR("se_get_run_profile failed");
		return err;
	}

	power_config_print(&profile);

	dcdc_reg_print();

	return 0;
}

#if CONFIG_POWER_CONFIGURATION
#define TEST_SCENARIO 2
#else
#define TEST_SCENARIO 0
#endif

#if TEST_SCENARIO == 0 /*default*/
#define ACLK_REDUCED 0
#define SE_SHUTDOWN 0
#define SYSTOP_SHUTDOWN 0
#define DBG_SHUTDOWN 0
#elif TEST_SCENARIO == 1
#define ACLK_REDUCED 0
#define SE_SHUTDOWN 0
#define SYSTOP_SHUTDOWN 0
#define DBG_SHUTDOWN 1
#elif TEST_SCENARIO == 2
#define ACLK_REDUCED 0
#define SE_SHUTDOWN 0
#define SYSTOP_SHUTDOWN 1
#define DBG_SHUTDOWN 1
#elif TEST_SCENARIO == 3
#define ACLK_REDUCED 0
#define SE_SHUTDOWN 1
#define SYSTOP_SHUTDOWN 1
#define DBG_SHUTDOWN 1
#elif TEST_SCENARIO == 4
#define ACLK_REDUCED 1
#define SE_SHUTDOWN 1
#define SYSTOP_SHUTDOWN 1
#define DBG_SHUTDOWN 1
#elif TEST_SCENARIO == 5
#define ACLK_REDUCED 1
#define SE_SHUTDOWN 0
#define SYSTOP_SHUTDOWN 1
#define DBG_SHUTDOWN 1
#else
#define ACLK_REDUCED 1
#define SE_SHUTDOWN 1
#define SYSTOP_SHUTDOWN 1
#define DBG_SHUTDOWN 0
#endif



/* BLE MODEM Power and Control and BLE Radio */
#define BLE_DOMAIN (PD1_MASK | PD7_MASK)

#define SE_DOMAIN     0 // (PD_SESS_MASK)
#define DEBUG_DOMAIN  (DBG_SHUTDOWN ? 0 : PD_DBSS_MASK)
#define SYSTOP_DOMAIN (SYSTOP_SHUTDOWN ? 0 : PD_SYST_MASK)

// #define USE_DEFAULT_DOMAINS 1

void power_config_set_sys_top(bool const systop_en, bool const dbgtop_en)
{
#define BSYS_PWR_REQ_OFFSET 0x400

	uint32_t pwr_req = sys_read32(HOST_BASE_SYS_CTRL + BSYS_PWR_REQ_OFFSET);

	pwr_req &= ~((0x7 << 3) + (0x1 << 2)); /* Clear SYSTOP_PWR_REQ & DBGTOP_PWR_REQ */
	pwr_req |= ((systop_en ? 0x2 : 0) << 3);  /* Set SYSTOP_PWR_REQ */
	pwr_req |= ((dbgtop_en ? 0x1 : 0) << 2);  /* Set DBGTOP_PWR_REQ */

	sys_write32(pwr_req, HOST_BASE_SYS_CTRL + BSYS_PWR_REQ_OFFSET);
}

#if DT_PROP(DT_CHOSEN(zephyr_hci_uart), clock_frequency) == 160000000
#define HE_CORE_CLOCK CLOCK_FREQUENCY_160MHZ
#elif DT_PROP(DT_CHOSEN(zephyr_hci_uart), clock_frequency) == 120000000
#define HE_CORE_CLOCK CLOCK_FREQUENCY_120MHZ
#elif DT_PROP(DT_CHOSEN(zephyr_hci_uart), clock_frequency) == 80000000
#define HE_CORE_CLOCK CLOCK_FREQUENCY_80MHZ
#elif DT_PROP(DT_CHOSEN(zephyr_hci_uart), clock_frequency) == 60000000
#define HE_CORE_CLOCK CLOCK_FREQUENCY_60MHZ
#else
#error "Unknown clock frequency"
#endif

struct CGU_Regs {
        union {
                uint32_t val;
                struct {
                        uint32_t SYS_XTAL_SEL : 1;
                        uint32_t RESERVED1 : 3;
                        uint32_t PERIPH_XTAL_SEL : 1;
                        uint32_t RESERVED2 : 11;
                        uint32_t CLKMON_ENA: 1;
                        uint32_t RESERVED3 : 3;
                        uint32_t XTAL_DEAD : 1;
                        uint32_t RESERVED4 : 11;
                };
        } OSC_CTRL;
        union {
                uint32_t val;
                struct {
                        uint32_t PLL_LOCK : 1;
                        uint32_t RESERVED1 : 3;
                        uint32_t PLL_CALIB : 1;
                        uint32_t RESERVED2 : 27;
                };
        } PLL_LOCK_CTRL;
        union {
                uint32_t val;
                struct {
                        uint32_t SYSREF : 1;
                        uint32_t RESERVED1 : 3;
                        uint32_t SYS : 1;
                        uint32_t RESERVED2 : 15;
                        uint32_t ES1 : 1;
                        uint32_t RESERVED3 : 11;
                };
        } PLL_CLK_SEL;
        uint32_t RESERVED;
        union {
                uint32_t val;
                struct {
                        uint32_t RESERVED1 : 4;
                        uint32_t ES1_PLL : 2;
                        uint32_t RESERVED2 : 6;
                        uint32_t ES1_OSC : 2;
                        uint32_t RESERVED3 : 2;
                        uint32_t REF_DIV_VAL : 11;
                        uint32_t REF_DIV_ENA : 1;
                        uint32_t RESERVED4 : 4;

                };
        } ESCLK_SEL;
        union {
                uint32_t val;
                struct {
                        uint32_t SYSPLL : 1;
                        uint32_t RESERVED1 : 12;
                        uint32_t ES1 : 1;
                        uint32_t RESERVED2 : 4;
                        uint32_t HFXO : 1;
                        uint32_t RESERVED3 : 1;
                        uint32_t CLK160M : 1;
                        uint32_t RESERVED4 : 2;
                        uint32_t CLK38P4M : 1;
                        uint32_t RESERVED5 : 8;
                };
        } CLK_ENA;
};

volatile struct CGU_Regs *cgu_regs = (volatile struct CGU_Regs *)CGU_BASE;

volatile struct CGU_Regs cgu_regs_start;
volatile struct CGU_Regs cgu_regs_start2;
volatile struct CGU_Regs cgu_regs_stop;

int power_config_set_default(void)
{
        cgu_regs_start.OSC_CTRL.val = sys_read32(CGU_BASE + 0x0);
        cgu_regs_start.PLL_LOCK_CTRL.val = sys_read32(CGU_BASE + 0x4);
        cgu_regs_start.PLL_CLK_SEL.val = sys_read32(CGU_BASE + 0x8);
        cgu_regs_start.ESCLK_SEL.val = sys_read32(CGU_BASE + 0x10);
        cgu_regs_start.CLK_ENA.val = sys_read32(CGU_BASE + 0x14);

	int err;
	run_profile_t profile = {
		.power_domains = PD_VBAT_AON_MASK | PD_SSE700_AON_MASK | PD_RTSS_HE_MASK |
				 PD_SESS_MASK | PD_SYST_MASK | PD_DBSS_MASK,
		.dcdc_voltage = 800, /* default = 825 */
		.dcdc_mode = DCDC_MODE_PFM_FORCED,
		.aon_clk_src = CLK_SRC_LFXO,
		.run_clk_src = CLK_SRC_PLL,
		.cpu_clk_freq = HE_CORE_CLOCK,
		.scaled_clk_freq = SCALED_FREQ_XO_LOW_DIV_38_4_MHZ,
		.memory_blocks = MRAM_MASK,
		.ip_clock_gating = 0, /* deprecated */
		.phy_pwr_gating = 0,
		.vdd_ioflex_3V3 = IOFLEX_LEVEL_1V8,
	};

	err = se_service_set_run_cfg(&profile);

        /* Fix DCDC since DK has no proper trims */
	sys_write32(0x0a004411, 0x1a60a034);
	sys_write32(0x1e11e701, 0x1a60a030);

        if (err) {
		LOG_ERR("Failed to set run profile, err %d", err);
	}

        cgu_regs_start2.OSC_CTRL.val = sys_read32(CGU_BASE + 0x0);
        cgu_regs_start2.PLL_LOCK_CTRL.val = sys_read32(CGU_BASE + 0x4);
        cgu_regs_start2.PLL_CLK_SEL.val = sys_read32(CGU_BASE + 0x8);
        cgu_regs_start2.ESCLK_SEL.val = sys_read32(CGU_BASE + 0x10);
        cgu_regs_start2.CLK_ENA.val = sys_read32(CGU_BASE + 0x14);

        return err;
}

int power_config_set(void)
{
	/* Write to BSYS_PWR_REQ at 0x1a010400 first,
	 * then use the service for turning off systop & dbgtop,
	 * then the service for turning off the SE.
	 */
	//power_config_set_sys_top(true, !DBG_SHUTDOWN);

	int err;
	run_profile_t profile = {
#if USE_DEFAULT_DOMAINS
		.power_domains = PD_SYST_MASK | PD_DBSS_MASK,
#else
		.power_domains = PD_VBAT_AON_MASK | PD_SSE700_AON_MASK | PD_RTSS_HE_MASK |
				 SYSTOP_DOMAIN | DEBUG_DOMAIN | BLE_DOMAIN | SE_DOMAIN,
#endif
		.dcdc_voltage = 800, /* default = 825 */
		.dcdc_mode = DCDC_MODE_PFM_FORCED,
		.aon_clk_src = CLK_SRC_LFXO,
#if RC_CLOCK_ENABLED
		.run_clk_src = CLK_SRC_HFRC,
		.cpu_clk_freq = CLOCK_FREQUENCY_76_8_RC_MHZ,
		.scaled_clk_freq = SCALED_FREQ_RC_ACTIVE_76_8_MHZ, // divider. adjust this...
#elif HFXO_ENABLED
		.run_clk_src = CLK_SRC_HFXO,
		.cpu_clk_freq = CLOCK_FREQUENCY_76_8_XO_MHZ,
		.scaled_clk_freq = SCALED_FREQ_RC_ACTIVE_38_4_MHZ,
#else
		.run_clk_src = CLK_SRC_PLL,
		.cpu_clk_freq = HE_CORE_CLOCK,
		.scaled_clk_freq = SCALED_FREQ_XO_LOW_DIV_38_4_MHZ,
#endif
		.memory_blocks = 0,
		.ip_clock_gating = 0, /* deprecated */
		.phy_pwr_gating = 0,
		.vdd_ioflex_3V3 = IOFLEX_LEVEL_1V8,
	};

#if HE_ITCM_RETENTION
	profile.memory_blocks |= SRAM4_1_MASK | SRAM4_2_MASK | SRAM4_3_MASK | SRAM4_4_MASK;
#endif
#if HE_DTCM_RETENTION
	profile.memory_blocks |= SRAM5_1_MASK | SRAM5_2_MASK | SRAM5_3_MASK | SRAM5_4_MASK |
				 SRAM5_5_MASK | SRAM2_MASK | SRAM3_MASK;
#endif
#if SE_RAM_RETENTION
	profile.memory_blocks |= SERAM_1_MASK | SERAM_2_MASK | SERAM_3_MASK | SERAM_4_MASK;
#endif
#if MRAM_RETENTION || TEST_SCENARIO == 0
	profile.memory_blocks |= MRAM_MASK;
#endif

	err = se_service_set_run_cfg(&profile);
	if (err) {
		LOG_ERR("Failed to set run profile, err %d", err);
		return err;
	}
	// LOG_INF("Run profile set successfully");

	// power_config_print(&profile);

	// dcdc_reg_print();

#define SYST_ACLK_CTRL 0x820
#define SYST_ACLK_DIV0 0x824

#if ACLK_REDUCED
        /* SYSPLL_CLK divided by ACLK_DIV0[CLKDIV] */
	// sys_write32(0x2, HOST_BASE_SYS_CTRL + SYST_ACLK_CTRL);
	sys_write32(ACLK_REDUCED, HOST_BASE_SYS_CTRL + SYST_ACLK_DIV0);
#endif

#if SE_SHUTDOWN
	err = se_service_se_sleep_req(0 /* se_params */);
	if (err) {
		LOG_ERR("Failed to set SE to sleep, err %d", err);
		return err;
	}
	//LOG_INF("SE set to sleep successfully");
#endif

        union dcdc_voltage_reg1 reg1 = {
                .raw = 0x1e11e701,
        };

#if (TEST_SCENARIO == 3 || TEST_SCENARIO == 4) && 0
        /* adjust trim a bit to get it back on .792V */
        reg1.dcdc_trim_vout -= 1;
#endif
        /* Fix DCDC since DK has no proper trims */
	sys_write32(0x0a004411, DCDC_VOLTAGE_REG2);
	sys_write32(reg1.raw, DCDC_VOLTAGE_REG1);

	//power_config_set_sys_top(!SYSTOP_SHUTDOWN, !DBG_SHUTDOWN);

        cgu_regs_stop.OSC_CTRL.val = sys_read32(CGU_BASE + 0x0);
        cgu_regs_stop.PLL_LOCK_CTRL.val = sys_read32(CGU_BASE + 0x4);
        cgu_regs_stop.PLL_CLK_SEL.val = sys_read32(CGU_BASE + 0x8);
        cgu_regs_stop.ESCLK_SEL.val = sys_read32(CGU_BASE + 0x10);
        cgu_regs_stop.CLK_ENA.val = sys_read32(CGU_BASE + 0x14);

#if CONFIG_USE_DYNAMIC_CLOCK_ADJUSTMENT
        uint32_t reg;
#if 0
        #define ESCLK_SEL (CGU_BASE + 0x10)
        #define ESCLK_SEL_ES1_OSC_MASK (0x3 << 12)

        reg = sys_read32(ESCLK_SEL);
        reg &= ~ESCLK_SEL_ES1_OSC_MASK;
        reg |= ESCLK_SEL_ES1_OSC_MASK;
        sys_write32(reg, ESCLK_SEL);
#endif

        #define MISC_REG1 (AON_BASE + 0x30)
        #define MISC_REG1_CLKDIV (0xF << 12)
#if 0
        reg = sys_read32(MISC_REG1);
        reg &= ~MISC_REG1_CLKDIV;
        reg |= (0x3 << 12); /* divide by 8 */
        //reg |= (0x4 << 12); /* divide by 16 */
        sys_write32(reg, MISC_REG1);
#endif

        (void)reg;
#endif

	return 0;
}
```

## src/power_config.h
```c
#ifndef __POWER_CONFIG_H__
#define __POWER_CONFIG_H__

#if !CONFIG_XIP && (CONFIG_POWER_CONFIGURATION || CONFIG_SYS_CLOCK_HW_CYCLES_PER_SEC < 160000000)

#define button_set_power 0

int power_config_set(void);
int power_config_get_and_print(void);
int power_config_set_default(void);

#define power_config_set_wrapper() power_config_set()
#define power_config_get_and_print_wrapper() power_config_get_and_print()
#define power_config_set_default_wrapper() power_config_set_default()

#else
#define power_config_set_wrapper() 0
#define power_config_get_and_print_wrapper()
#define power_config_set_default_wrapper()
#endif

#endif /* __POWER_CONFIG_H__ */
```
